# STM32L4R9xx register map
File version: 1.0
Registers are 32-bit, access not given, reset 0x0 unless marked. A register's access mark holds for its fields unless they carry their own. Offsets are from the block's base; [hi:lo] are bit positions; {n}, {i} and the like mark numbered series; 'fields as' and 'values as' point back to an identical list.

## LTDC
Base 0x40016800
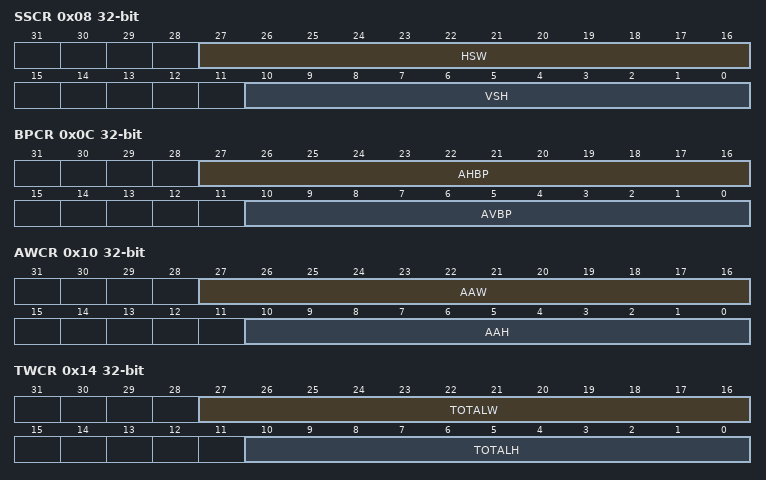
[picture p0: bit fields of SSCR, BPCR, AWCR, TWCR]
0x08 SSCR
  [27:16] HSW, [10:0] VSH
0x0C BPCR
  [27:16] AHBP, [10:0] AVBP
0x10 AWCR
  [27:16] AAW, [10:0] AAH
0x14 TWCR
  [27:16] TOTALW, [10:0] TOTALH
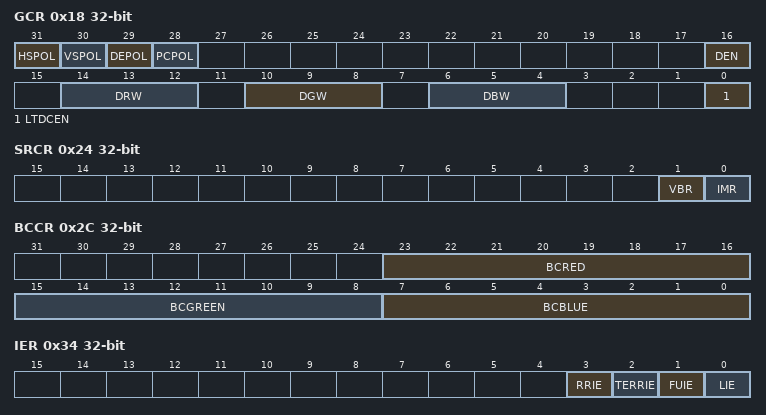
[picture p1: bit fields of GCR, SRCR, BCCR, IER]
0x18 GCR
  [31] HSPOL, [30] VSPOL, [29] DEPOL, [28] PCPOL, [16] DEN, [14:12] DRW, [10:8] DGW, [6:4] DBW, [0] LTDCEN
0x24 SRCR
  [1] VBR, [0] IMR
0x2C BCCR
  [23:16] BCRED, [15:8] BCGREEN, [7:0] BCBLUE
0x34 IER
  [3] RRIE, [2] TERRIE, [1] FUIE, [0] LIE
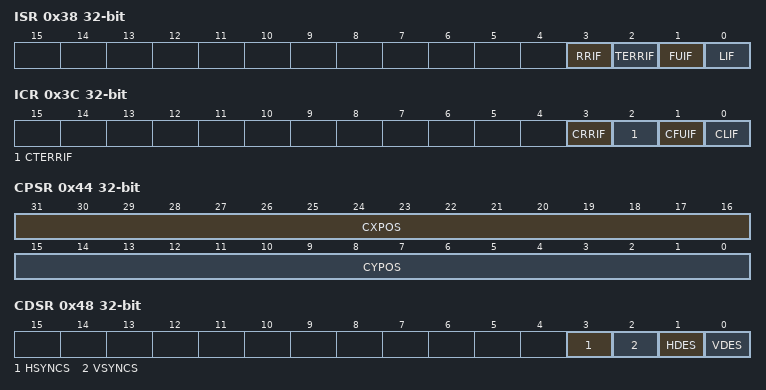
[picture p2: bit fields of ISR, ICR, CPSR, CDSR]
0x38 ISR
  [3] RRIF, [2] TERRIF, [1] FUIF, [0] LIF
0x3C ICR
  [3] CRRIF, [2] CTERRIF, [1] CFUIF, [0] CLIF
0x40 LIPCR
  [10:0] LIPOS
0x44 CPSR
  [31:16] CXPOS, [15:0] CYPOS
0x48 CDSR
  [3] HSYNCS, [2] VSYNCS, [1] HDES, [0] VDES
0x84 CR1
0x88 WHPCR1
0x90 WVPCR1
0x9C CKCR1
0xAC PFCR1
0xC0 CACR1
0xD8 DCCR1
0xF4 BFCR1
0x104 CR2
0x108 WHPCR2
0x110 WVPCR2
0x11C CFBAR1
0x11C CKCR2
0x12C PFCR2
0x140 CACR2
0x148 CFBLR1
0x158 DCCR2
0x174 BFCR2
0x178 CFBLNR1
0x19C CFBAR2
0x1B8 CLUTWR1
0x1C8 CFBLR2
0x1F8 CFBLNR2
0x238 CLUTWR2

## DMA1
Base 0x40020000
Same registers: DMA2 0x40020400
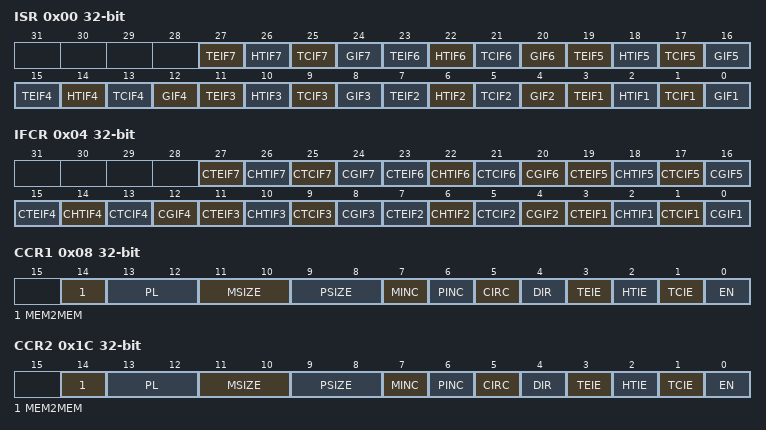
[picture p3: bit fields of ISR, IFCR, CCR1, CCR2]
0x00 ISR
  [4n-1] TEIF{n} (n=1..7), [4n-2] HTIF{n} (n=1..7), [4n-3] TCIF{n} (n=1..7), [4n-4] GIF{n} (n=1..7)
0x04 IFCR
  [4n-1] CTEIF{n} (n=1..7), [4n-2] CHTIF{n} (n=1..7), [4n-3] CTCIF{n} (n=1..7), [4n-4] CGIF{n} (n=1..7)
0x08 CCR1
  [14] MEM2MEM, [13:12] PL, [11:10] MSIZE, [9:8] PSIZE, [7] MINC, [6] PINC, [5] CIRC, [4] DIR, [3] TEIE, [2] HTIE, [1] TCIE, [0] EN
0x0C CNDTR1
  [15:0] NDT
{0x0+0x14*i} CPAR{i} (i=1..7)
  [31:0] PA
0x1C CCR2
  fields as CCR1
{0xC+0x14*i} CMAR{i} (i=1..7)
  [31:0] MA
0x20 CNDTR2
  [15:0] NDT
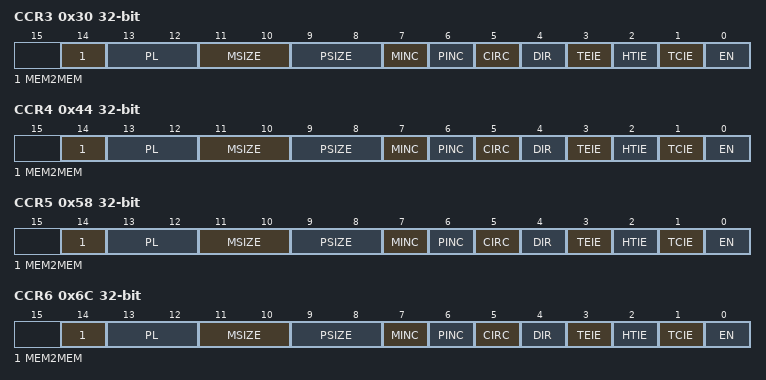
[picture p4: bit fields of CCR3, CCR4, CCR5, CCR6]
0x30 CCR3
  fields as CCR1
0x34 CNDTR3
  [15:0] NDT
0x44 CCR4
  fields as CCR1
0x48 CNDTR4
  [15:0] NDT
0x58 CCR5
  fields as CCR1
0x5C CNDTR5
  [15:0] NDT
0x6C CCR6
  fields as CCR1
0x70 CNDTR6
  [15:0] NDT
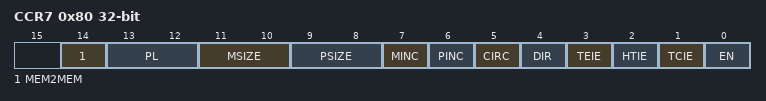
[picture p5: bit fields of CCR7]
0x80 CCR7
  fields as CCR1
0x84 CNDTR7
  [15:0] NDT

## DMAMUX1
Base 0x40020800
0x00 CCR0
0x04 CCR1
0x08 CCR2
0x0C CCR3
{0x0+4i} CCR{i} (i=4..9)
0x28 CCR0
0x2C CCR1
0x30 CCR2
0x34 CCR3
0x80 CCRs
0x100 CCR0
0x104 CCR1
0x108 CCR2
0x10C CCR3
0x140 CCRs

## FLASH
Base 0x40022000
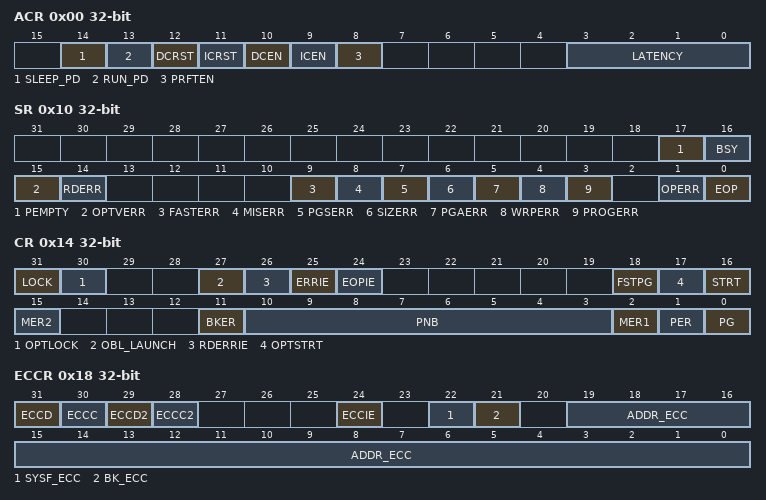
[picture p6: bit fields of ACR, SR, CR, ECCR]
0x00 ACR
  [14] SLEEP_PD, [13] RUN_PD, [12] DCRST, [11] ICRST, [10] DCEN, [9] ICEN, [8] PRFTEN, [3:0] LATENCY
0x04 PDKEYR
0x08 KEYR
0x0C OPTKEYR
0x10 SR
  [17] PEMPTY, [16] BSY, [15] OPTVERR, [14] RDERR, [9] FASTERR, [8] MISERR, [7] PGSERR, [6] SIZERR, [5] PGAERR, [4] WRPERR, [3] PROGERR, [1] OPERR, [0] EOP
0x14 CR
  [31] LOCK, [30] OPTLOCK, [27] OBL_LAUNCH, [26] RDERRIE, [25] ERRIE, [24] EOPIE, [18] FSTPG, [17] OPTSTRT, [16] STRT, [15] MER2, [11] BKER, [10:3] PNB, [2] MER1, [1] PER, [0] PG
0x18 ECCR
  [31] ECCD, [30] ECCC, [29] ECCD2, [28] ECCC2, [24] ECCIE, [22] SYSF_ECC, [21] BK_ECC, [19:0] ADDR_ECC
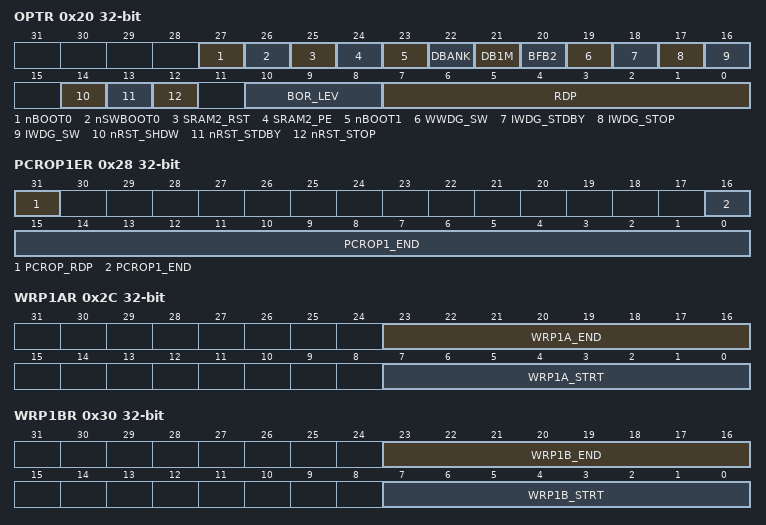
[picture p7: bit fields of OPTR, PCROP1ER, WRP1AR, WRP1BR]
0x20 OPTR
  [27] nBOOT0, [26] nSWBOOT0, [25] SRAM2_RST, [24] SRAM2_PE, [23] nBOOT1, [22] DBANK, [21] DB1M, [20] BFB2, [19] WWDG_SW, [18] IWDG_STDBY, [17] IWDG_STOP, [16] IWDG_SW, [14] nRST_SHDW, [13] nRST_STDBY, [12] nRST_STOP, [10:8] BOR_LEV, [7:0] RDP
0x24 PCROP1SR
  [16:0] PCROP1_STRT
0x28 PCROP1ER
  [31] PCROP_RDP, [16:0] PCROP1_END
0x2C WRP1AR
  [23:16] WRP1A_END, [7:0] WRP1A_STRT
0x30 WRP1BR
  [23:16] WRP1B_END, [7:0] WRP1B_STRT
0x44 PCROP2SR
  [16:0] PCROP2_STRT
0x48 PCROP2ER
  [16:0] PCROP2_END
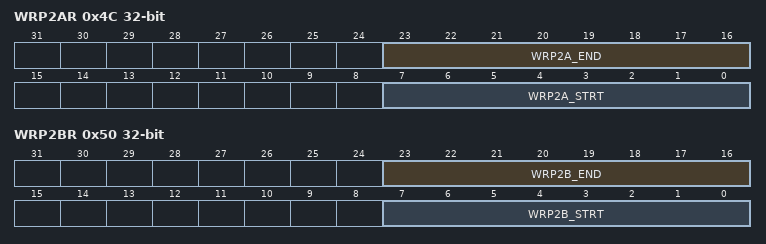
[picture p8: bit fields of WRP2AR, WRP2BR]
0x4C WRP2AR
  [23:16] WRP2A_END, [7:0] WRP2A_STRT
0x50 WRP2BR
  [23:16] WRP2B_END, [7:0] WRP2B_STRT
0x130 CFGR
  [0] LVEN

## CRC
Base 0x40023000
0x00 DR
0x04 IDR
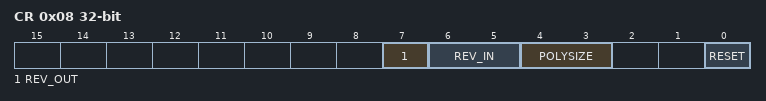
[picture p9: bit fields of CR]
0x08 CR
  [7] REV_OUT, [6:5] REV_IN, [4:3] POLYSIZE, [0] RESET
0x10 INIT
0x14 POL

## TSC
Base 0x40024000
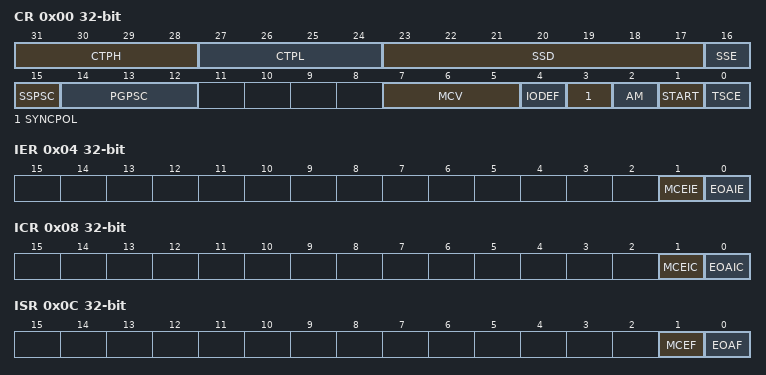
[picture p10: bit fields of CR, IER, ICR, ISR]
0x00 CR
  [31:28] CTPH, [27:24] CTPL, [23:17] SSD, [16] SSE, [15] SSPSC, [14:12] PGPSC, [7:5] MCV, [4] IODEF, [3] SYNCPOL, [2] AM, [1] START, [0] TSCE
0x04 IER
  [1] MCEIE, [0] EOAIE
0x08 ICR
  [1] MCEIC, [0] EOAIC
0x0C ISR
  [1] MCEF, [0] EOAF
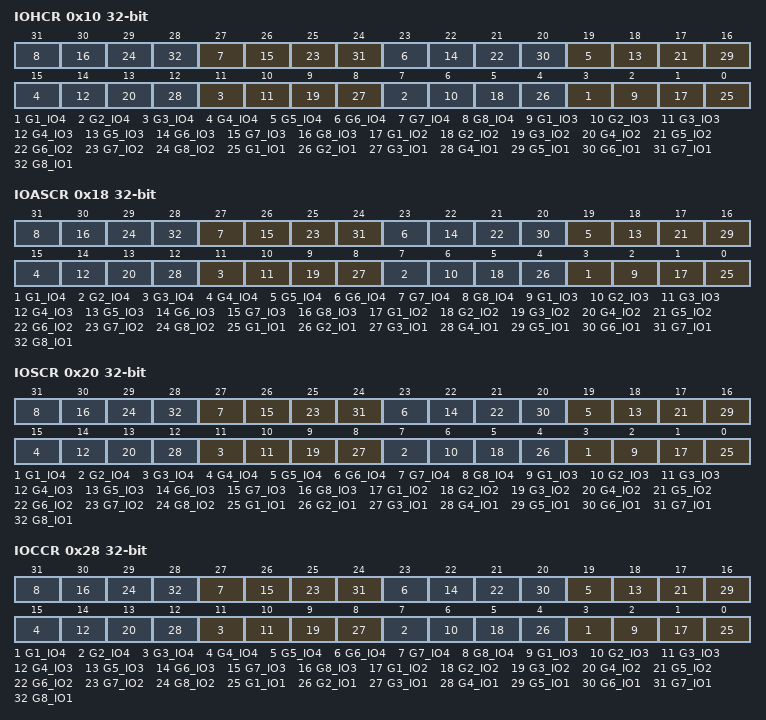
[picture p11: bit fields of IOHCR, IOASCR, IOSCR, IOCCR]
0x10 IOHCR
  [4n-1] G{n}_IO4 (n=1..8), [4n-2] G{n}_IO3 (n=1..8), [4n-3] G{n}_IO2 (n=1..8), [4n-4] G{n}_IO1 (n=1..8)
0x18 IOASCR
  fields as IOHCR
0x20 IOSCR
  fields as IOHCR
0x28 IOCCR
  fields as IOHCR
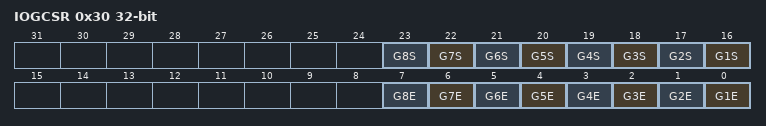
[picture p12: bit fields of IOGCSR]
0x30 IOGCSR
  [n+15] G{n}S (n=1..8), [n-1] G{n}E (n=1..8)
0x34 IOGXCR.0
  [13:0] CNT
0x38 IOGXCR.1
  [13:0] CNT
0x3C IOGXCR.2
  [13:0] CNT
0x40 IOGXCR.3
  [13:0] CNT
0x44 IOGXCR.4
  [13:0] CNT
0x48 IOGXCR.5
  [13:0] CNT
0x4C IOGXCR.6
  [13:0] CNT
0x50 IOGXCR.7
  [13:0] CNT
